# MK30D7 register map
File version: 1.6
Registers are 32-bit, read-write, reset 0x0 unless marked. A register's access mark holds for its fields unless they carry their own. Offsets are from the block's base; [hi:lo] are bit positions; {n}, {i} and the like mark numbered series.

## ADC0 — Analog-to-Digital Converter
Base 0x4003B000; register names take the prefix ADC0_
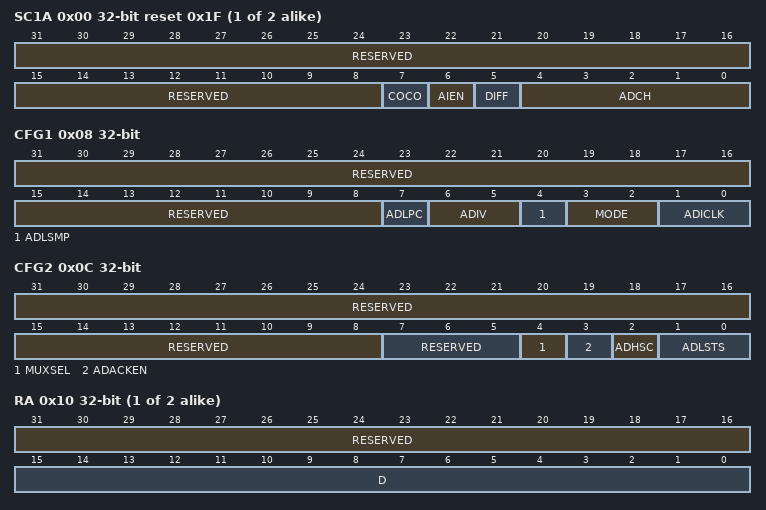
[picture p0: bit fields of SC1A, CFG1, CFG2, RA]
0x00 SC1{x} (x=A,B; step 0x4) access per field reset 0x1F — ADC status and control registers 1
  [31:8] RESERVED ro
  [7] COCO ro — Conversion complete flag
    0=Conversion not completed; 1=Conversion completed
  [6] AIEN rw — Interrupt enable
    0=Conversion complete interrupt disabled; 1=Conversion complete interrupt enabled
  [5] DIFF rw — Differential mode enable
    0=Single-ended conversions and input channels are selected; 1=Differential conversions and input channels are selected
  [4:0] ADCH rw — Input channel select
    {v}=When DIFF=0, DADP{v} is selected as input; when DIFF=1, DAD{v} is selected as input (v=0..3); {v}=When DIFF=0, AD{v} is selected as input; when DIFF=1, it is reserved (v=4..23); 26=When DIFF=0, Temp sensor (single-ended) is selected as input; when DIFF=1, Temp sensor (differential) is selected as input; 27=When DIFF=0, Bandgap (single-ended) is selected as input; when DIFF=1, Bandgap (differential) is selected as input; 29=When DIFF=0, VREFSH is selected as input; when DIFF=1, -VREFSH (differential) is selected as input. Voltage reference selected is determined by the REFSEL bits in the SC2 register.; 30=When DIFF=0, VREFSL is selected as input; when DIFF=1, it is reserved. Voltage reference selected is determined by the REFSEL bits in the SC2 register.; 31=Module disabled
0x08 CFG1 access per field — ADC configuration register 1
  [31:8] RESERVED ro
  [7] ADLPC rw — Low-power configuration
    0=Normal power configuration; 1=Low power configuration. The power is reduced at the expense of maximum clock speed.
  [6:5] ADIV rw — Clock divide select
    0=The divide ratio is 1 and the clock rate is input clock; 1=The divide ratio is 2 and the clock rate is (input clock)/2; 2=The divide ratio is 4 and the clock rate is (input clock)/4; 3=The divide ratio is 8 and the clock rate is (input clock)/8
  [4] ADLSMP rw — Sample time configuration
    0=Short sample time; 1=Long sample time
  [3:2] MODE rw — Conversion mode selection
    0=When DIFF=0: It is single-ended 8-bit conversion; when DIFF=1, it is differential 9-bit conversion with 2's complement output; 1=When DIFF=0: It is single-ended 12-bit conversion; when DIFF=1, it is differential 13-bit conversion with 2's complement output; 2=When DIFF=0: It is single-ended 10-bit conversion; when DIFF=1, it is differential 11-bit conversion with 2's complement output; 3=When DIFF=0: It is single-ended 16-bit conversion; when DIFF=1, it is differential 16-bit conversion with 2's complement output 
  [1:0] ADICLK rw — Input clock select
    0=Bus clock; 1=Bus clock divided by 2; 2=Alternate clock (ALTCLK); 3=Asynchronous clock (ADACK)
0x0C CFG2 access per field — Configuration register 2
  [31:8] RESERVED ro
  [7:5] RESERVED ro
  [4] MUXSEL rw — ADC Mux select
    0=ADxxa channels are selected; 1=ADxxb channels are selected
  [3] ADACKEN rw — Asynchronous clock output enable
    0=Asynchronous clock output disabled; Asynchronous clock only enabled if selected by ADICLK and a conversion is active; 1=Asynchronous clock and clock output enabled regardless of the state of the ADC
  [2] ADHSC rw — High speed configuration
    0=Normal conversion sequence selected; 1=High speed conversion sequence selected (2 additional ADCK cycles to total conversion time)
  [1:0] ADLSTS rw — Long sample time select
    0=Default longest sample time (20 extra ADCK cycles; 24 ADCK cycles total); 1=12 extra ADCK cycles; 16 ADCK cycles total sample time; 2=6 extra ADCK cycles; 10 ADCK cycles total sample time; 3=2 extra ADCK cycles; 6 ADCK cycles total sample time
0x10 R{x} (x=A,B; step 0x4) ro — ADC data result register
  [31:16] RESERVED
  [15:0] D — Data result
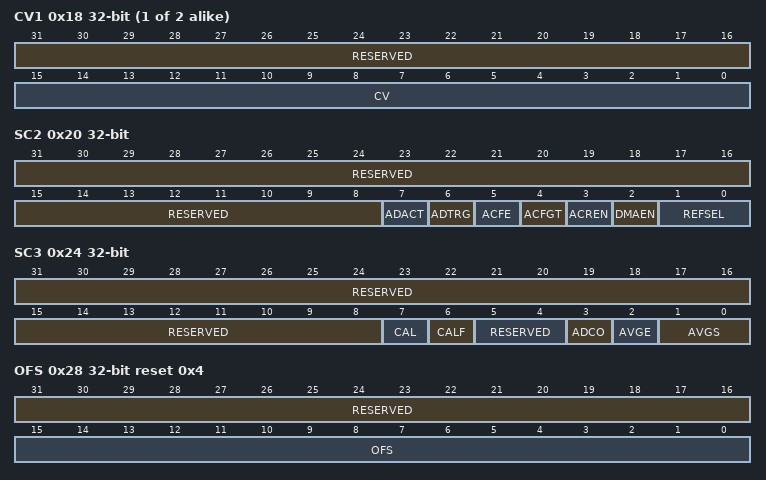
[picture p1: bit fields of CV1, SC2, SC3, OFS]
{0x14+4i} CV{i} (i=1..2) access per field — Compare value registers
  [31:16] RESERVED ro
  [15:0] CV rw — Compare value
0x20 SC2 access per field — Status and control register 2
  [31:8] RESERVED ro
  [7] ADACT ro — Conversion active
    0=Conversion not in progress; 1=Conversion in progress
  [6] ADTRG rw — Conversion trigger select
    0=Software trigger selected; 1=Hardware trigger selected
  [5] ACFE rw — Compare function enable
    0=Compare function disabled; 1=Compare function enabled
  [4] ACFGT rw — Compare function greater than enable
    0=Configures less than threshold, outside range not inclusive and inside range not inclusive functionality based on the values placed in the CV1 and CV2 registers; 1=Configures greater than or equal to threshold, outside range inclusive and inside range inclusive functionality based on the values placed in the CV1 and CV2 registers
  [3] ACREN rw — Compare function range enable
    0=Range function disabled. Only the compare value 1 register (CV1) is compared.; 1=Range function enabled. Both compare value registers (CV1 and CV2) are compared.
  [2] DMAEN rw — DMA enable
    0=DMA is disabled; 1=DMA is enabled and will assert the ADC DMA request during a ADC conversion complete event noted by the assertion of any of the ADC COCO flags
  [1:0] REFSEL rw — Voltage reference selection
    0=Default voltage reference pin pair (external pins VREFH and VREFL); 1=Alternate reference pair (VALTH and VALTL). This pair may be additional external pins or internal sources depending on MCU configuration. Consult the Chip Configuration information for details specific to this MCU.
0x24 SC3 access per field — Status and control register 3
  [31:8] RESERVED ro
  [7] CAL rw — Calibration
  [6] CALF ro — Calibration failed flag
    0=Calibration completed normally; 1=Calibration failed. ADC accuracy specifications are not guaranteed.
  [5:4] RESERVED ro
  [3] ADCO rw — Continuous conversion enable
    0=One conversion or one set of conversions if the hardware average function is enabled (AVGE=1) after initiating a conversion; 1=Continuous conversions or sets of conversions if the hardware average function is enabled (AVGE=1) after initiating a conversion
  [2] AVGE rw — Hardware average enable
    0=Hardware average function disabled; 1=Hardware average function enabled
  [1:0] AVGS rw — Hardware average select
    0=4 samples averaged; 1=8 samples averaged; 2=16 samples averaged; 3=32 samples averaged
0x28 OFS access per field reset 0x4 — ADC offset correction register
  [31:16] RESERVED ro
  [15:0] OFS rw — Offset error correction value
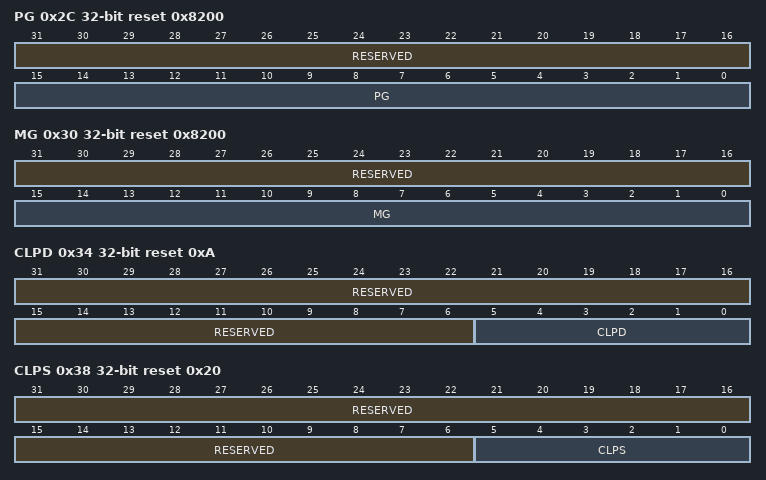
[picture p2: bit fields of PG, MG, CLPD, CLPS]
0x2C PG access per field reset 0x8200 — ADC plus-side gain register
  [31:16] RESERVED ro
  [15:0] PG rw — Plus-side gain
0x30 MG access per field reset 0x8200 — ADC minus-side gain register
  [31:16] RESERVED ro
  [15:0] MG rw — Minus-side gain
0x34 CLPD access per field reset 0xA — ADC plus-side general calibration value register
  [31:6] RESERVED ro, [5:0] CLPD rw
0x38 CLPS access per field reset 0x20 — ADC plus-side general calibration value register
  [31:6] RESERVED ro, [5:0] CLPS rw
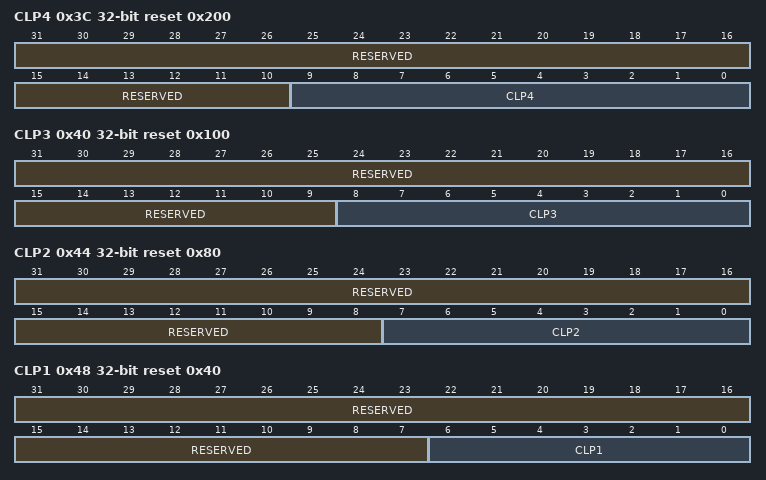
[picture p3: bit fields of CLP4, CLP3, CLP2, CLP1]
0x3C CLP4 access per field reset 0x200 — ADC plus-side general calibration value register
  [31:10] RESERVED ro, [9:0] CLP4 rw
0x40 CLP3 access per field reset 0x100 — ADC plus-side general calibration value register
  [31:9] RESERVED ro, [8:0] CLP3 rw
0x44 CLP2 access per field reset 0x80 — ADC plus-side general calibration value register
  [31:8] RESERVED ro, [7:0] CLP2 rw
0x48 CLP1 access per field reset 0x40 — ADC plus-side general calibration value register
  [31:7] RESERVED ro, [6:0] CLP1 rw
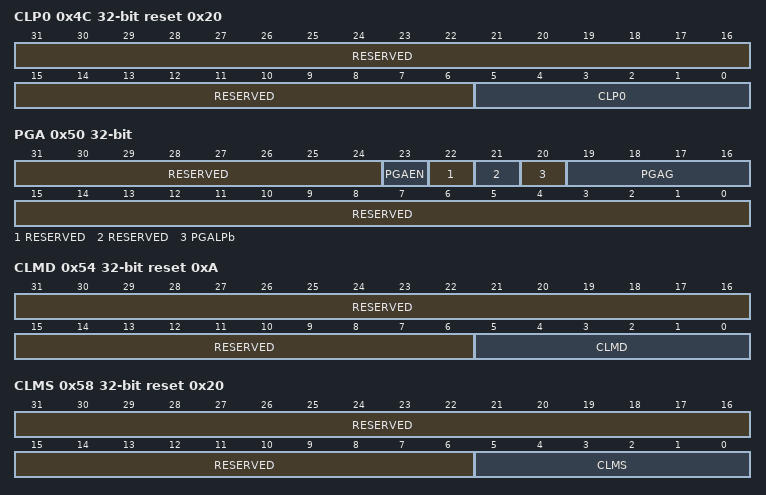
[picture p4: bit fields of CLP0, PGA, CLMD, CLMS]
0x4C CLP0 access per field reset 0x20 — ADC plus-side general calibration value register
  [31:6] RESERVED ro, [5:0] CLP0 rw
0x50 PGA access per field — ADC PGA register
  [31:24] RESERVED ro
  [23] PGAEN rw — PGA enable
    0=PGA disabled; 1=PGA enabled
  [22] RESERVED ro
  [21] RESERVED wo
  [20] PGALPb rw — PGA low-power mode control
    0=PGA runs in low power mode; 1=PGA runs in normal power mode
  [19:16] PGAG rw — PGA gain setting
    0=1; 1=2; 2=4; 3=8; 4=16; 5=32; 6=64
  [15:0] RESERVED ro
0x54 CLMD access per field reset 0xA — ADC minus-side general calibration value register
  [31:6] RESERVED ro, [5:0] CLMD rw
0x58 CLMS access per field reset 0x20 — ADC minus-side general calibration value register
  [31:6] RESERVED ro, [5:0] CLMS rw
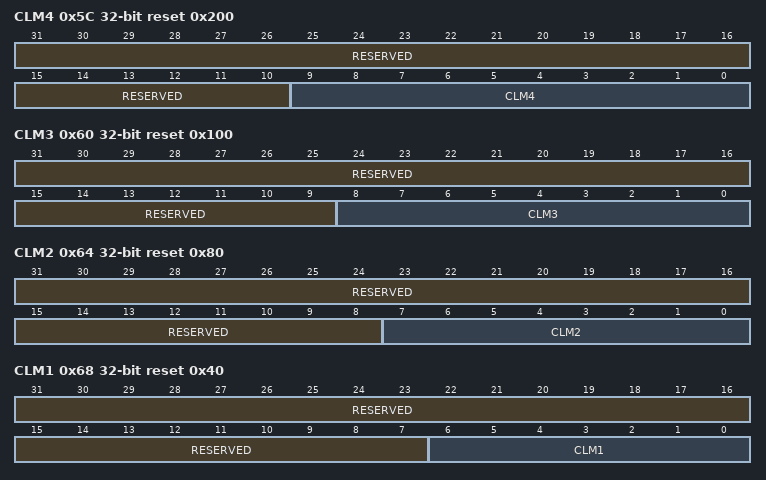
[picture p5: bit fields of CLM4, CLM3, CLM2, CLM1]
0x5C CLM4 access per field reset 0x200 — ADC minus-side general calibration value register
  [31:10] RESERVED ro, [9:0] CLM4 rw
0x60 CLM3 access per field reset 0x100 — ADC minus-side general calibration value register
  [31:9] RESERVED ro, [8:0] CLM3 rw
0x64 CLM2 access per field reset 0x80 — ADC minus-side general calibration value register
  [31:8] RESERVED ro, [7:0] CLM2 rw
0x68 CLM1 access per field reset 0x40 — ADC minus-side general calibration value register
  [31:7] RESERVED ro, [6:0] CLM1 rw
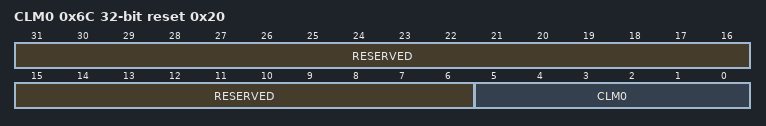
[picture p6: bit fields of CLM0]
0x6C CLM0 access per field reset 0x20 — ADC minus-side general calibration value register
  [31:6] RESERVED ro, [5:0] CLM0 rw

## ADC1 — Analog-to-Digital Converter
Base 0x400BB000; register names take the prefix ADC1_
Registers as ADC0.
